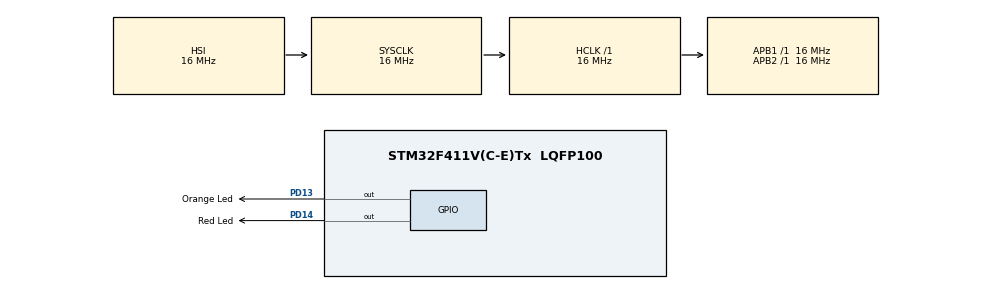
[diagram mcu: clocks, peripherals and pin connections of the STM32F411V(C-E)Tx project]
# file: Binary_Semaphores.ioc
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FREERTOS.Tasks01=defaultTask,0,128,StartDefaultTask,Default,NULL
Mcu.Family=STM32F4
Mcu.Name=STM32F411V(C-E)Tx
Mcu.Package=LQFP100
NVIC.PriorityGroup=NVIC_PRIORITYGROUP_4
NVIC.TIM1_UP_TIM10_IRQn=true\:0\:0\:false\:false\:true\:false\:false
NVIC.TimeBase=TIM1_UP_TIM10_IRQn
NVIC.TimeBaseIP=TIM1
PD13.GPIO_Label=Orange Led
PD13.GPIO_Speed=GPIO_SPEED_FREQ_VERY_HIGH
PD13.Signal=GPIO_Output
PD14.GPIO_Label=Red Led
PD14.GPIO_Speed=GPIO_SPEED_FREQ_VERY_HIGH
PD14.Signal=GPIO_Output
ProjectManager.HeapSize=0x200
ProjectManager.StackSize=0x400
ProjectManager.TargetToolchain=MDK-ARM V5
RCC.AHBFreq_Value=16000000
RCC.APB1Freq_Value=16000000
RCC.APB2Freq_Value=16000000
RCC.CortexFreq_Value=16000000
RCC.HSE_VALUE=25000000
RCC.HSI_VALUE=16000000
RCC.LSE_VALUE=32768
RCC.SYSCLKFreq_VALUE=16000000
RCC.VCOOutputFreq_Value=192000000
VP_FREERTOS_VS_ENABLE.Mode=Enabled
VP_SYS_VS_tim1.Mode=TIM1
board=custom

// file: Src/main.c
/**
  ******************************************************************************
  * @file           : main.c
  * @brief          : Main program body
  ******************************************************************************
  * This notice applies to any and all portions of this file
  * that are not between comment pairs USER CODE BEGIN and
  * USER CODE END. Other portions of this file, whether
  * inserted by the user or by software development tools
  * are owned by their respective copyright owners.
  *
  * Copyright (c) 2018 STMicroelectronics International N.V.
  * All rights reserved.
  *
  * Redistribution and use in source and binary forms, with or without
  * modification, are permitted, provided that the following conditions are met:
  *
  * 1. Redistribution of source code must retain the above copyright notice,
  *    this list of conditions and the following disclaimer.
  * 2. Redistributions in binary form must reproduce the above copyright notice,
  *    this list of conditions and the following disclaimer in the documentation
  *    and/or other materials provided with the distribution.
  * 3. Neither the name of STMicroelectronics nor the names of other
  *    contributors to this software may be used to endorse or promote products
  *    derived from this software without specific written permission.
  * 4. This software, including modifications and/or derivative works of this
  *    software, must execute solely and exclusively on microcontroller or
  *    microprocessor devices manufactured by or for STMicroelectronics.
  * 5. Redistribution and use of this software other than as permitted under
  *    this license is void and will automatically terminate your rights under
  *    this license.
  *
  * THIS SOFTWARE IS PROVIDED BY STMICROELECTRONICS AND CONTRIBUTORS "AS IS"
  * AND ANY EXPRESS, IMPLIED OR STATUTORY WARRANTIES, INCLUDING, BUT NOT
  * LIMITED TO, THE IMPLIED WARRANTIES OF MERCHANTABILITY, FITNESS FOR A
  * PARTICULAR PURPOSE AND NON-INFRINGEMENT OF THIRD PARTY INTELLECTUAL PROPERTY
  * RIGHTS ARE DISCLAIMED TO THE FULLEST EXTENT PERMITTED BY LAW. IN NO EVENT
  * SHALL STMICROELECTRONICS OR CONTRIBUTORS BE LIABLE FOR ANY DIRECT, INDIRECT,
  * INCIDENTAL, SPECIAL, EXEMPLARY, OR CONSEQUENTIAL DAMAGES (INCLUDING, BUT NOT
  * LIMITED TO, PROCUREMENT OF SUBSTITUTE GOODS OR SERVICES; LOSS OF USE, DATA,
  * OR PROFITS; OR BUSINESS INTERRUPTION) HOWEVER CAUSED AND ON ANY THEORY OF
  * LIABILITY, WHETHER IN CONTRACT, STRICT LIABILITY, OR TORT (INCLUDING
  * NEGLIGENCE OR OTHERWISE) ARISING IN ANY WAY OUT OF THE USE OF THIS SOFTWARE,
  * EVEN IF ADVISED OF THE POSSIBILITY OF SUCH DAMAGE.
  *
  ******************************************************************************
  */
#include "main.h"
#include "stm32f4xx_hal.h"
#include "cmsis_os.h"

/* USER CODE BEGIN Includes */
#include <string.h>
/* USER CODE END Includes */

osThreadId defaultTaskHandle;

/* USER CODE BEGIN PV */
/* Private variables ---------------------------------------------------------*/
#define STACK_SIZE 128
uint8_t data;
SemaphoreHandle_t xSemaphore;
TaskHandle_t xhandle1,xhandle2;
/* USER CODE END PV */

void SystemClock_Config(void);
static void MX_GPIO_Init(void);
void StartDefaultTask(void const * argument);

/* USER CODE BEGIN PFP */
/* Private function prototypes -----------------------------------------------*/
void myTask1(void *argument);
void myTask2(void *argument);
/* USER CODE END PFP */

int main(void)
{

  /* MCU Configuration----------------------------------------------------------*/

  /* Reset of all peripherals, Initializes the Flash interface and the Systick. */
  HAL_Init();

  /* Configure the system clock */
  SystemClock_Config();

  /* Initialize all configured peripherals */
  MX_GPIO_Init();

  /* USER CODE BEGIN RTOS_SEMAPHORES */
  /* add semaphores, ... */
	vSemaphoreCreateBinary(xSemaphore);
	/*xSemaphore = xSemaphoreCreateMutex();
	if(xSemaphore == NULL)
	{
		Error_Handler();
	}*/
  /* USER CODE END RTOS_SEMAPHORES */

  /* Create the thread(s) */
  /* definition and creation of defaultTask */
  osThreadDef(defaultTask, StartDefaultTask, osPriorityNormal, 0, 128);
  defaultTaskHandle = osThreadCreate(osThread(defaultTask), NULL);

  /* USER CODE BEGIN RTOS_THREADS */
  /* add threads, ... */
	if(xTaskCreate(myTask1, "TASK1", STACK_SIZE, NULL, osPriorityNormal - osPriorityIdle, xhandle1) != pdPASS)
	{
		Error_Handler();
	}
	if(xTaskCreate(myTask2, "TASK2", STACK_SIZE, NULL, osPriorityNormal - osPriorityIdle, xhandle2) != pdPASS)
	{
		Error_Handler();
	}
  /* USER CODE END RTOS_THREADS */

  /* Start scheduler */
  osKernelStart();

  /* We should never get here as control is now taken by the scheduler */

  /* Infinite loop */
  while (1)
  {

  }

}

void SystemClock_Config(void)
{

  RCC_OscInitTypeDef RCC_OscInitStruct;
  RCC_ClkInitTypeDef RCC_ClkInitStruct;

    /**Configure the main internal regulator output voltage
    */
  __HAL_RCC_PWR_CLK_ENABLE();

  __HAL_PWR_VOLTAGESCALING_CONFIG(PWR_REGULATOR_VOLTAGE_SCALE1);

    /**Initializes the CPU, AHB and APB busses clocks
    */
  RCC_OscInitStruct.OscillatorType = RCC_OSCILLATORTYPE_HSI;
  RCC_OscInitStruct.HSIState = RCC_HSI_ON;
  RCC_OscInitStruct.HSICalibrationValue = 16;
  RCC_OscInitStruct.PLL.PLLState = RCC_PLL_NONE;
  if (HAL_RCC_OscConfig(&RCC_OscInitStruct) != HAL_OK)
  {
    _Error_Handler(__FILE__, __LINE__);
  }

    /**Initializes the CPU, AHB and APB busses clocks
    */
  RCC_ClkInitStruct.ClockType = RCC_CLOCKTYPE_HCLK|RCC_CLOCKTYPE_SYSCLK
                              |RCC_CLOCKTYPE_PCLK1|RCC_CLOCKTYPE_PCLK2;
  RCC_ClkInitStruct.SYSCLKSource = RCC_SYSCLKSOURCE_HSI;
  RCC_ClkInitStruct.AHBCLKDivider = RCC_SYSCLK_DIV1;
  RCC_ClkInitStruct.APB1CLKDivider = RCC_HCLK_DIV1;
  RCC_ClkInitStruct.APB2CLKDivider = RCC_HCLK_DIV1;

  if (HAL_RCC_ClockConfig(&RCC_ClkInitStruct, FLASH_LATENCY_0) != HAL_OK)
  {
    _Error_Handler(__FILE__, __LINE__);
  }

    /**Configure the Systick interrupt time
    */
  HAL_SYSTICK_Config(HAL_RCC_GetHCLKFreq()/1000);

    /**Configure the Systick
    */
  HAL_SYSTICK_CLKSourceConfig(SYSTICK_CLKSOURCE_HCLK);

  /* SysTick_IRQn interrupt configuration */
  HAL_NVIC_SetPriority(SysTick_IRQn, 15, 0);
}

/** Configure pins as
        * Analog
        * Input
        * Output
        * EVENT_OUT
        * EXTI
*/
static void MX_GPIO_Init(void)
{

  GPIO_InitTypeDef GPIO_InitStruct;

  /* GPIO Ports Clock Enable */
  __HAL_RCC_GPIOD_CLK_ENABLE();

  /*Configure GPIO pin Output Level */
  HAL_GPIO_WritePin(GPIOD, Orange_Led_Pin|Red_Led_Pin, GPIO_PIN_RESET);

  /*Configure GPIO pins : Orange_Led_Pin Red_Led_Pin */
  GPIO_InitStruct.Pin = Orange_Led_Pin|Red_Led_Pin;
  GPIO_InitStruct.Mode = GPIO_MODE_OUTPUT_PP;
  GPIO_InitStruct.Pull = GPIO_NOPULL;
  GPIO_InitStruct.Speed = GPIO_SPEED_FREQ_VERY_HIGH;
  HAL_GPIO_Init(GPIOD, &GPIO_InitStruct);

}

/* USER CODE BEGIN 4 */
void myTask1(void *argument)
{
  /* Infinite loop */
  for(;;)
  {
		osDelay(1000);
		if(xSemaphoreTake(xSemaphore, 100) == pdTRUE)
		{
			data++;
			xSemaphoreGive(xSemaphore);
		}
  }
}
void myTask2(void *argument)
{
  /* Infinite loop */
  for(;;)
  {
		osDelay(1000);
		if(xSemaphoreTake(xSemaphore, 100) == pdTRUE)
		{
			printf("data => %u\n",data);
			xSemaphoreGive(xSemaphore);
		}
  }
}
/* USER CODE END 4 */

/* StartDefaultTask function */
void StartDefaultTask(void const * argument)
{

  /* USER CODE BEGIN 5 */
	//Infinite loop
  for(;;)
  {
		HAL_GPIO_TogglePin(GPIOD, Orange_Led_Pin);
		osDelay(1000);
	}
  /* USER CODE END 5 */
}

void HAL_TIM_PeriodElapsedCallback(TIM_HandleTypeDef *htim)
{
  if (htim->Instance == TIM1) {
    HAL_IncTick();
  }
}

void _Error_Handler(char *file, int line)
{
  /* USER CODE BEGIN Error_Handler_Debug */
  /* User can add his own implementation to report the HAL error return state */
	HAL_GPIO_WritePin(GPIOD, Red_Led_Pin, GPIO_PIN_SET);
  while(1)
  {
  }
  /* USER CODE END Error_Handler_Debug */
}

/************************ (C) COPYRIGHT STMicroelectronics *****END OF FILE****/
